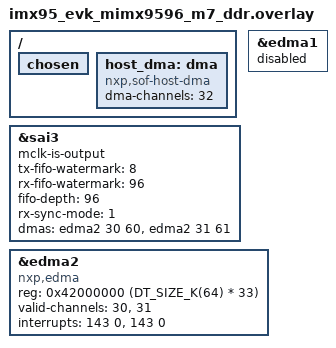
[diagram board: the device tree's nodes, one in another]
/*
 * Copyright 2024 NXP
 *
 * SPDX-License-Identifier: Apache-2.0
 */

/ {
	/* this'll select Cortex-M SysTick as the system timer */
	chosen {
		/delete-property/ zephyr,system-timer;
	};

	host_dma: dma {
		compatible = "nxp,sof-host-dma";
		dma-channels = <32>;
		#dma-cells = <0>;
	};
};

&sai3 {
	/*
	 * The WM8962 is the bit-clock/frame-sync provider and takes its MCLK
	 * from the SAI3 MCLK output (Linux DTS: wm8962 mclk = IMX95_CLK_SAI3
	 * @ 12.288 MHz). The SAI must therefore drive its MCLK pin: without
	 * mclk-is-output the nxp,dai-sai driver leaves MCLK gated, the codec
	 * gets no SYSCLK (WM8962 "DC servo timed out"), never generates BCLK,
	 * and the SAI TX FIFO/eDMA never drain -> playback stalls (-EIO).
	 */
	mclk-is-output;
	tx-fifo-watermark = <8>;
	rx-fifo-watermark = <96>;
	fifo-depth = <96>;
	rx-sync-mode = <1>;
	dmas = <&edma2 30 60>, <&edma2 31 61>;
	status = "okay";
};

&edma1 {
	status = "disabled";
};

&edma2 {
	compatible = "nxp,edma";
	reg = <0x42000000 (DT_SIZE_K(64) * 33)>;
	valid-channels = <30>, <31>;
	interrupts = <143 0>, <143 0>;
	/delete-property/ nxp,version;
	/delete-property/ dma-channels;
	/delete-property/ dma-requests;
	/delete-property/ no-error-irq;
	/delete-property/ channels-shared-irq-mask;
	status = "okay";
};
